# EFR32MG24A010F1024IM40 register map
Vendor: Silicon Labs; Series: EFR32; File version: B
Registers are 32-bit, read-write, reset 0x0 unless marked. A register's access mark holds for its fields unless they carry their own. Offsets are from the block's base; [hi:lo] are bit positions; {n}, {i} and the like mark numbered series; 'fields as' and 'values as' point back to an identical list.

## ICACHE0_S — ICACHE0_S Registers
Base 0x40034000
Same registers: ICACHE0_NS 0x50034000
0x00 IPVERSION ro — The read only IPVERSION field gives the version for this module. There may be minor software changes required for modules with different values of IPVERSION.
  [31:0] IPVERSION — IP version ID
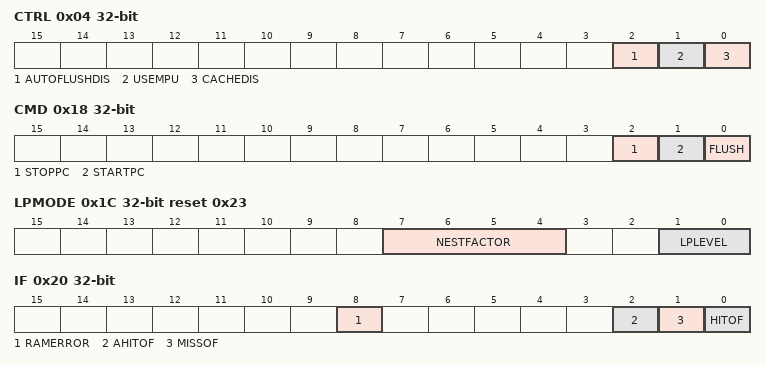
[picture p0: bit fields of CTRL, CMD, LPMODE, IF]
0x04 CTRL
  [2] AUTOFLUSHDIS — Automatic Flushing Disable
  [1] USEMPU
  [0] CACHEDIS — Cache Disable
0x08 PCHITS ro
  [31:0] PCHITS — Performance Counter Hits
0x0C PCMISSES ro
  [31:0] PCMISSES — Performance Counter Misses
0x10 PCAHITS ro
  [31:0] PCAHITS — Performance Counter Advanced Hits
0x14 STATUS ro
  [0] PCRUNNING
0x18 CMD wo
  [2] STOPPC — Stop Performance Counters
  [1] STARTPC — Start Performance Counters
  [0] FLUSH
0x1C LPMODE reset 0x23
  [7:4] NESTFACTOR — Low Power Nest Factor
  [1:0] LPLEVEL — Low Power Level
    0=BASIC (Base instruction cache functionality); 1=ADVANCED (Advanced buffering mode, where the cache uses the fetch pattern to predict highly accessed data and store it in low-energy memory); 3=MINACTIVITY (Minimum activity mode, which allows the cache to minimize activity in logic that it predicts has a low probability being used. This mode can introduce wait-states into the instruction fetch stream when the cache exits one of its low-activity states. The number of wait-states introduced is small, but users running with 0-wait-state memory and wishing to reduce the variability that the cache might introduce with additional wait-states may wish to lower the cache low-power level. Note, this mode includes the advanced buffering mode functionality.)
0x20 IF
  [8] RAMERROR — RAM error Interrupt Flag
  [2] AHITOF — Advanced Hit Overflow Interrupt Flag
  [1] MISSOF — Miss Overflow Interrupt Flag
  [0] HITOF — Hit Overflow Interrupt Flag
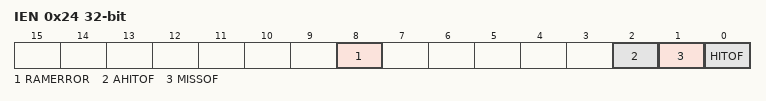
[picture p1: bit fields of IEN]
0x24 IEN
  [8] RAMERROR — RAM error Interrupt Enable
  [2] AHITOF — Advanced Hit Overflow Interrupt Enable
  [1] MISSOF — Miss Overflow Interrupt Enable
  [0] HITOF — Hit Overflow Interrupt Enable

## LDMAXBAR_S — LDMAXBAR_S Registers
Base 0x40044000
Same registers: LDMAXBAR_NS 0x50044000
0x00 IPVERSION ro reset 0x3
  [31:0] IPVERSION — IP Version ID
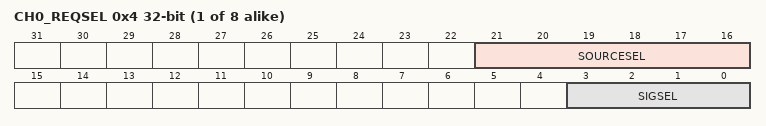
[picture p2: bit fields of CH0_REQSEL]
{0x4+4i} CH{i}_REQSEL (i=0..7)
  [21:16] SOURCESEL — Source Select
  [3:0] SIGSEL — Signal Select

## BURTC_S — BURTC_S Registers
Base 0x40064000
Same registers: BURTC_NS 0x50064000
0x00 IPVERSION ro reset 0x1
  [31:0] IPVERSION — IP Version ID
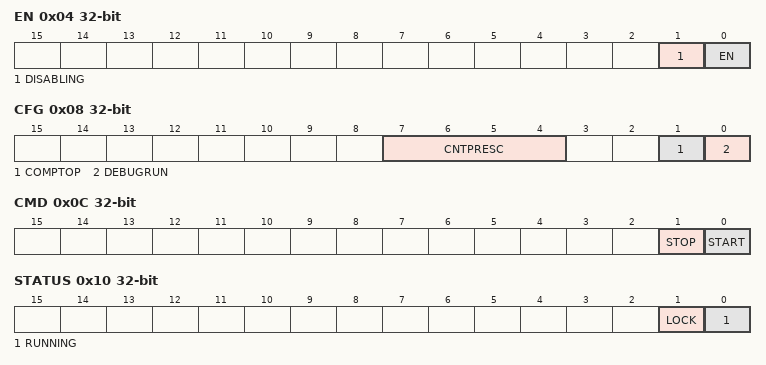
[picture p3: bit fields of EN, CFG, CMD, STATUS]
0x04 EN
  [1] DISABLING ro — Disablement busy status
  [0] EN — BURTC Enable
0x08 CFG
  [7:4] CNTPRESC — Counter prescaler value.
    0=DIV1 (CLK_CNT = (BURTC LF CLK)/1); 1=DIV2 (CLK_CNT = (BURTC LF CLK)/2); 2=DIV4 (CLK_CNT = (BURTC LF CLK)/4); 3=DIV8 (CLK_CNT = (BURTC LF CLK)/8); 4=DIV16 (CLK_CNT = (BURTC LF CLK)/16); 5=DIV32 (CLK_CNT = (BURTC LF CLK)/32); 6=DIV64 (CLK_CNT = (BURTC LF CLK)/64); 7=DIV128 (CLK_CNT = (BURTC LF CLK)/128); 8=DIV256 (CLK_CNT = (BURTC LF CLK)/256); 9=DIV512 (CLK_CNT = (BURTC LF CLK)/512); 10=DIV1024 (CLK_CNT = (BURTC LF CLK)/1024); 11=DIV2048 (CLK_CNT = (BURTC LF CLK)/2048); 12=DIV4096 (CLK_CNT = (BURTC LF CLK)/4096); 13=DIV8192 (CLK_CNT = (BURTC LF CLK)/8192); 14=DIV16384 (CLK_CNT = (BURTC LF CLK)/16384); 15=DIV32768 (CLK_CNT = (BURTC LF CLK)/32768)
  [1] COMPTOP — Compare Channel is Top Value
    0=DISABLE (The top value of the BURTC is 4294967295 (0xFFFFFFFF)); 1=ENABLE (The top value of the BURTC is given by COMP)
  [0] DEBUGRUN — Debug Mode Run Enable
    0=BURTC is frozen in debug mode; 1=BURTC is running in debug mode
0x0C CMD wo
  [1] STOP — Stop BURTC counter
  [0] START — Start BURTC counter
0x10 STATUS ro
  [1] LOCK — Configuration Lock Status
    0=UNLOCKED (All BURTC lockable registers are unlocked.); 1=LOCKED (All BURTC lockable registers are locked.)
  [0] RUNNING — BURTC running status
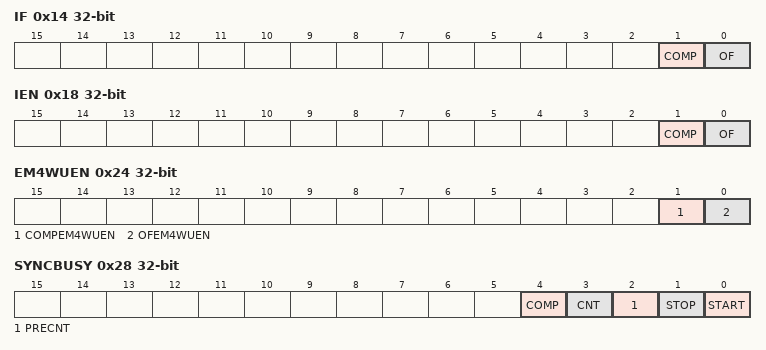
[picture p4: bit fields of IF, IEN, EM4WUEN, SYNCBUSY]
0x14 IF
  [1] COMP — Compare Match Interrupt Flag
  [0] OF — Overflow Interrupt Flag
0x18 IEN
  fields as IF
0x1C PRECNT
  [14:0] PRECNT — Pre-Counter Value
0x20 CNT
  [31:0] CNT — Counter Value
0x24 EM4WUEN
  [1] COMPEM4WUEN — Compare Match EM4 Wakeup Enable
  [0] OFEM4WUEN — Overflow EM4 Wakeup Enable
0x28 SYNCBUSY ro
  [4] COMP — Sync busy for COMP
  [3] CNT — Sync busy for CNT
  [2] PRECNT — Sync busy for PRECNT
  [1] STOP — Sync busy for STOP
  [0] START — Sync busy for START
0x2C LOCK wo reset 0xAEE8
  [15:0] LOCKKEY — Configuration Lock Key
    0xAEE8=UNLOCK (Write to unlock all BURTC lockable registers)
0x30 COMP
  [31:0] COMP — Compare Value
